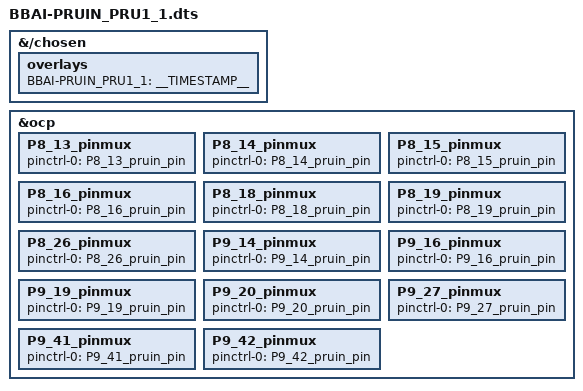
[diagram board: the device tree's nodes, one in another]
/*
 * Copyright (C) 2020 Deepak Khatri <deepaklorkhatri7@gmail.com>
 * See Cape Interface Spec page for more info on Bone Buses
 * https://elinux.org/Beagleboard:BeagleBone_cape_interface_spec
 *
 * Virtual cape for pr1_pru1_gpi* pins
 *
 * This program is free software; you can redistribute it and/or modify
 * it under the terms of the GNU General Public License version 2 as
 * published by the Free Software Foundation.
 */
/dts-v1/;
/plugin/;

/*
* Helper to show loaded overlays under: /proc/device-tree/chosen/overlays/
*/
&{/chosen} {
    overlays {
        BBAI-PRUIN_PRU1_1 = __TIMESTAMP__;
    };
};

/*
 * Update the default pinmux of the pins.
 * See these files for the phandles (&P9_* & &P8_*)
 * BeagleBoard-DeviceTrees/v4.19.x-ti-overlays/src/arm/am335x-bone-common-univ.dtsi
 * BeagleBoard-DeviceTrees/v4.19.x-ti-overlays/src/arm/am572x-bone-common-univ.dtsi
 */
&ocp {
    P8_13_pinmux { pinctrl-0 = <&P8_13_pruin_pin>; }; /* pr1_pru1_gpi7 */
    P8_14_pinmux { pinctrl-0 = <&P8_14_pruin_pin>; }; /* pr1_pru1_gpi9 */
    P8_15_pinmux { pinctrl-0 = <&P8_15_pruin_pin>; }; /* pr1_pru1_gpi16 */
    P8_16_pinmux { pinctrl-0 = <&P8_16_pruin_pin>; }; /* pr1_pru1_gpi18 */
    P8_18_pinmux { pinctrl-0 = <&P8_18_pruin_pin>; }; /* pr1_pru1_gpi5 */
    P8_19_pinmux { pinctrl-0 = <&P8_19_pruin_pin>; }; /* pr1_pru1_gpi6 */
    P8_26_pinmux { pinctrl-0 = <&P8_26_pruin_pin>; }; /* pr1_pru1_gpi17 */

    P9_14_pinmux { pinctrl-0 = <&P9_14_pruin_pin>; }; /* pr1_pru1_gpi14 */
    P9_16_pinmux { pinctrl-0 = <&P9_16_pruin_pin>; }; /* pr1_pru1_gpi15 */
    P9_19_pinmux { pinctrl-0 = <&P9_19_pruin_pin>; }; /* pr1_pru1_gpi2 */
    P9_20_pinmux { pinctrl-0 = <&P9_20_pruin_pin>; }; /* pr1_pru1_gpi1 */
    P9_27_pinmux { pinctrl-0 = <&P9_27_pruin_pin>; }; /* pr1_pru1_gpi11 */
    P9_41_pinmux { pinctrl-0 = <&P9_41_pruin_pin>; }; /* pr1_pru1_gpi3 */
    P9_42_pinmux { pinctrl-0 = <&P9_42_pruin_pin>; }; /* pr1_pru1_gpi10 */
};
